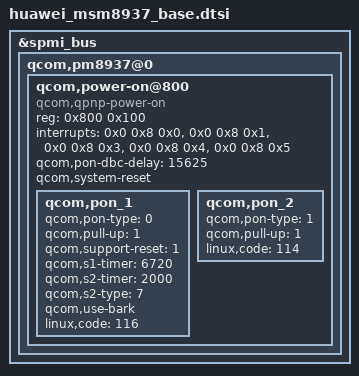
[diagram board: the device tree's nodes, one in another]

/*=============================================================================
                           Huawei Base Dtsi File
  GENERAL DESCRIPTION
    This file is for include the Communal node

  Copyright 2010-2014 by HUAWEI Technologies, Inc.  All Rights Reserved.
=============================================================================*/
#include "msm8937.dtsi"
#include "msm8937-pmi8937-qrd-sku2.dtsi"
&spmi_bus {
	qcom,pm8937@0 {
		qcom,power-on@800 {
                        compatible = "qcom,qpnp-power-on";
                        reg = <0x800 0x100>;
                        interrupts = <0x0 0x8 0x0>,
                                <0x0 0x8 0x1>,
                                <0x0 0x8 0x3>,
                                <0x0 0x8 0x4>,
                                <0x0 0x8 0x5>;
                        interrupt-names = "kpdpwr", "resin", "kpdpwr-bark",
                                "resin-bark", "kpdpwr-resin-bark";
                        qcom,pon-dbc-delay = <15625>;
                        qcom,system-reset;
			qcom,pon_1 {
                                qcom,pon-type = <0>;
                                qcom,pull-up = <1>;
                                qcom,support-reset = <1>;
                                qcom,s1-timer = <6720>;
                                qcom,s2-timer = <2000>;
                                qcom,s2-type = <7>;
                                qcom,use-bark;
                                linux,code = <116>;
                        };

                        qcom,pon_2 {
                                qcom,pon-type = <1>;
                                qcom,pull-up = <1>;
                                linux,code = <114>;
                        };
                };
};
};
